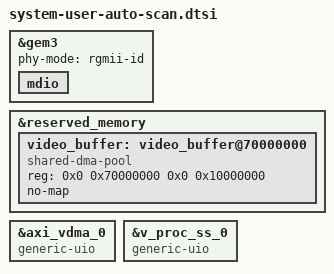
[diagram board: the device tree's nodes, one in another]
/include/ "system-conf.dtsi"
/ {
};

/* ============================================================
 * GEM3 以太网配置 - 自动扫描PHY版本
 * 
 * 使用场景：当不确定PHY地址时，让内核自动扫描MDIO总线
 * ============================================================ */
&gem3 {
    status = "okay";
    phy-mode = "rgmii-id";
    /* 注意：不指定phy-handle，让内核自动扫描所有地址 */
    
    mdio: mdio {
        #address-cells = <1>;
        #size-cells = <0>;
        /* 不定义具体的PHY节点，内核会扫描地址0-31 */
    };
};

/* ============================================================
 * 保留内存配置 - 用于视频帧缓冲
 * ============================================================ */
&reserved_memory {
    #address-cells = <2>;
    #size-cells = <2>;
    ranges;
    
    video_buffer: video_buffer@70000000 {
        compatible = "shared-dma-pool";
        reg = <0x0 0x70000000 0x0 0x10000000>;
        no-map;
    };
};

/* ============================================================
 * VDMA 配置 - 使用UIO驱动
 * ============================================================ */
&axi_vdma_0 {
    compatible = "generic-uio";
    status = "okay";
};

/* ============================================================
 * VPSS 配置 - 使用UIO驱动
 * ============================================================ */
&v_proc_ss_0 {
    compatible = "generic-uio";
    status = "okay";
};
